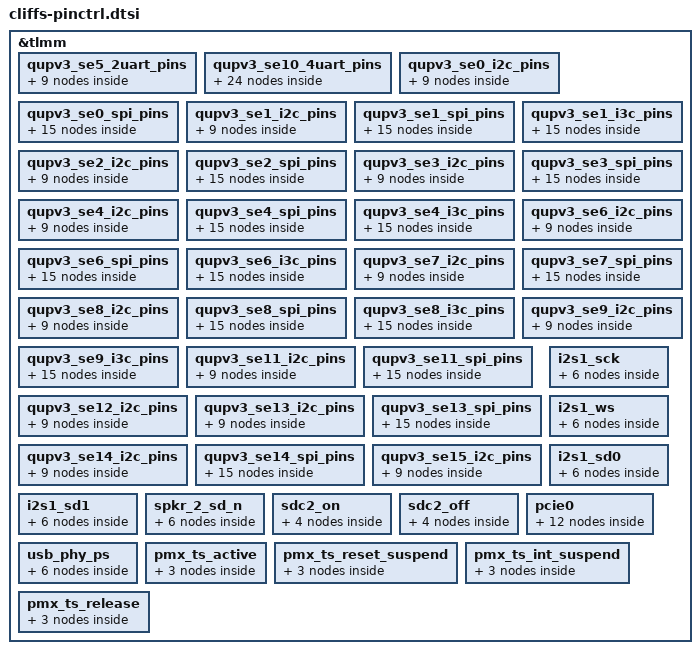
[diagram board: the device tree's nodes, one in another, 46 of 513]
&tlmm {
	qupv3_se5_2uart_pins: qupv3_se5_2uart_pins {
		qupv3_se5_2uart_tx_active: qupv3_se5_2uart_tx_active {
			mux {
				pins = "gpio22";
				function = "qup0_se5_l2";
			};

			config {
				pins = "gpio22";
				drive-strength = <2>;
				bias-disable;
			};
		};

		qupv3_se5_2uart_rx_active: qupv3_se5_2uart_rx_active {
			mux {
				pins = "gpio23";
				function = "qup0_se5_l3";
			};

			config {
				pins = "gpio23";
				drive-strength = <2>;
				bias-disable;
			};
		};

		qupv3_se5_2uart_sleep: qupv3_se5_2uart_sleep {
			mux {
				pins = "gpio22", "gpio23";
				function = "gpio";
			};

			config {
				pins = "gpio22", "gpio23";
				drive-strength = <2>;
				bias-pull-down;
			};
		};
	};

	qupv3_se10_4uart_pins: qupv3_se10_4uart_pins {
		qupv3_se10_default_cts: qupv3_se10_default_cts {
			mux {
				pins = "gpio40";
				function = "gpio";
			};

			config {
				pins = "gpio40";
				drive-strength = <2>;
				bias-disable;
			};
		};

		qupv3_se10_default_rts: qupv3_se10_default_rts {
			mux {
				pins = "gpio41";
				function = "gpio";
			};

			config {
				pins = "gpio41";
				drive-strength = <2>;
				bias-pull-down;
			};
		};

		qupv3_se10_default_tx: qupv3_se10_default_tx {
			mux {
				pins = "gpio42";
				function = "gpio";
			};

			config {
				pins = "gpio42";
				drive-strength = <2>;
				bias-pull-up;
			};
		};

		qupv3_se10_default_rx: qupv3_se10_default_rx {
			mux {
				pins = "gpio43";
				function = "gpio";
			};

			config {
				pins = "gpio43";
				drive-strength = <2>;
				bias-pull-down;
			};
		};

		qupv3_se10_cts: qupv3_se10_cts {
			mux {
				pins = "gpio40";
				function = "qup1_se2_l0";
			};

			config {
				pins = "gpio40";
				drive-strength = <2>;
				bias-disable;
			};
		};

		qupv3_se10_rts: qupv3_se10_rts {
			mux {
				pins = "gpio41";
				function = "qup1_se2_l1";
			};

			config {
				pins = "gpio41";
				drive-strength = <2>;
				bias-pull-down;
			};
		};

		qupv3_se10_tx: qupv3_se10_tx {
			mux {
				pins = "gpio42";
				function = "qup1_se2_l2";
			};

			config {
				pins = "gpio42";
				drive-strength = <2>;
				bias-pull-up;
			};
		};

		qupv3_se10_rx: qupv3_se10_rx {
			mux {
				pins = "gpio43";
				function = "qup1_se2_l3";
			};

			config {
				pins = "gpio43";
				drive-strength = <2>;
				bias-disable;
			};
		};
	};

	qupv3_se0_i2c_pins: qupv3_se0_i2c_pins {
		qupv3_se0_i2c_sda_active: qupv3_se0_i2c_sda_active {
			mux {
				pins = "gpio52";
				function = "qup0_se0_l0";
			};

			config {
				pins = "gpio52";
				drive-strength = <2>;
				bias-pull-up;
				qcom,i2c_pull;
			};
		};

		qupv3_se0_i2c_scl_active: qupv3_se0_i2c_scl_active {
			mux {
				pins = "gpio53";
				function = "qup0_se0_l1";
			};

			config {
				pins = "gpio53";
				drive-strength = <2>;
				bias-pull-up;
				qcom,i2c_pull;
			};
		};

		qupv3_se0_i2c_sleep: qupv3_se0_i2c_sleep {
			mux {
				pins = "gpio52", "gpio53";
				function = "gpio";
			};

			config {
				pins = "gpio52", "gpio53";
				drive-strength = <2>;
				//bias-disable; - Has strong PU
			};
		};
	};

	qupv3_se0_spi_pins: qupv3_se0_spi_pins {
		qupv3_se0_spi_miso_active: qupv3_se0_spi_miso_active {
			mux {
				pins = "gpio52";
				function = "qup0_se0_l0";
			};

			config {
				pins = "gpio52";
				drive-strength = <6>;
				bias-disable;
			};
		};

		qupv3_se0_spi_mosi_active: qupv3_se0_spi_mosi_active {
			mux {
				pins = "gpio53";
				function = "qup0_se0_l1";
			};

			config {
				pins = "gpio53";
				drive-strength = <6>;
				bias-disable;
			};
		};

		qupv3_se0_spi_clk_active: qupv3_se0_spi_clk_active {
			mux {
				pins = "gpio54";
				function = "qup0_se0_l2";
			};

			config {
				pins = "gpio54";
				drive-strength = <6>;
				bias-disable;
			};
		};

		qupv3_se0_spi_cs_active: qupv3_se0_spi_cs_active {
			mux {
				pins = "gpio55";
				function = "qup0_se0_l3";
			};

			config {
				pins = "gpio55";
				drive-strength = <6>;
				bias-disable;
			};
		};

		qupv3_se0_spi_sleep: qupv3_se0_spi_sleep {
			mux {
				pins = "gpio52", "gpio53",
					"gpio54", "gpio55";
				function = "gpio";
			};

			config {
				pins = "gpio52", "gpio53",
					"gpio54", "gpio55";
				drive-strength = <2>;
				bias-disable;
			};
		};
	};

	qupv3_se1_i2c_pins: qupv3_se1_i2c_pins {
		qupv3_se1_i2c_sda_active: qupv3_se1_i2c_sda_active {
			mux {
				pins = "gpio4";
				function = "qup0_se1_l0";
			};

			config {
				pins = "gpio4";
				drive-strength = <2>;
				bias-pull-up;
			};
		};

		qupv3_se1_i2c_scl_active: qupv3_se1_i2c_scl_active {
			mux {
				pins = "gpio5";
				function = "qup0_se1_l1";
			};

			config {
				pins = "gpio5";
				drive-strength = <2>;
				bias-pull-up;
			};
		};

		qupv3_se1_i2c_sleep: qupv3_se1_i2c_sleep {
			mux {
				pins = "gpio4", "gpio5";
				function = "gpio";
			};

			config {
				pins = "gpio4", "gpio5";
				drive-strength = <2>;
				bias-disable;
			};
		};
	};

	qupv3_se1_spi_pins: qupv3_se1_spi_pins {
		qupv3_se1_spi_miso_active: qupv3_se1_spi_miso_active {
			mux {
				pins = "gpio4";
				function = "qup0_se1_l0";
			};

			config {
				pins = "gpio4";
				drive-strength = <6>;
				bias-disable;
			};
		};

		qupv3_se1_spi_mosi_active: qupv3_se1_spi_mosi_active {
			mux {
				pins = "gpio5";
				function = "qup0_se1_l1";
			};

			config {
				pins = "gpio5";
				drive-strength = <6>;
				bias-disable;
			};
		};

		qupv3_se1_spi_clk_active: qupv3_se1_spi_clk_active {
			mux {
				pins = "gpio6";
				function = "qup0_se1_l2";
			};

			config {
				pins = "gpio6";
				drive-strength = <6>;
				bias-disable;
			};
		};

		qupv3_se1_spi_cs_active: qupv3_se1_spi_cs_active {
			mux {
				pins = "gpio7";
				function = "qup0_se1_l3";
			};

			config {
				pins = "gpio7";
				drive-strength = <6>;
				bias-disable;
			};
		};

		qupv3_se1_spi_sleep: qupv3_se1_spi_sleep {
			mux {
				pins = "gpio4", "gpio5",
					"gpio6", "gpio7";
				function = "gpio";
			};

			config {
				pins = "gpio4", "gpio5",
					"gpio6", "gpio7";
				drive-strength = <2>;
				bias-disable;
			};
		};
	};

	qupv3_se1_i3c_pins: qupv3_se1_i3c_pins {
		qupv3_se1_i3c_sda_active: qupv3_se1_i3c_sda_active {
			mux {
				pins = "gpio4";
				function = "ibi_i3c";
			};

			config {
				pins = "gpio4";
				drive-strength = <16>;
				bias-pull-up;
			};
		};

		qupv3_se1_i3c_scl_active: qupv3_se1_i3c_scl_active {
			mux {
				pins = "gpio5";
				function = "ibi_i3c";
			};

			config {
				pins = "gpio5";
				drive-strength = <16>;
				bias-pull-up;
			};
		};

		qupv3_se1_i3c_sda_sleep: qupv3_se1_i3c_sda_sleep {
			mux {
				pins = "gpio4";
				function = "ibi_i3c";
			};

			config {
				pins = "gpio4";
				drive-strength = <16>;
				bias-pull-up;
			};
		};

		qupv3_se1_i3c_scl_sleep: qupv3_se1_i3c_scl_sleep {
			mux {
				pins = "gpio5";
				function = "ibi_i3c";
			};

			config {
				pins = "gpio5";
				drive-strength = <16>;
				bias-pull-up;
			};
		};

		qupv3_se1_i3c_disable: qupv3_se1_i3c_disable {
			mux {
				pins = "gpio4", "gpio5";
				function = "gpio";
			};

			config {
				pins = "gpio4", "gpio5";
				drive-strength = <2>;
				bias-disable;
			};
		};
	};

	qupv3_se2_i2c_pins: qupv3_se2_i2c_pins {
		qupv3_se2_i2c_sda_active: qupv3_se2_i2c_sda_active {
			mux {
				pins = "gpio8";
				function = "qup0_se2_l0";
			};

			config {
				pins = "gpio8";
				drive-strength = <2>;
				bias-pull-up;
				qcom,i2c_pull;
			};
		};

		qupv3_se2_i2c_scl_active: qupv3_se2_i2c_scl_active {
			mux {
				pins = "gpio9";
				function = "qup0_se2_l1";
			};

			config {
				pins = "gpio9";
				drive-strength = <2>;
				bias-pull-up;
				qcom,i2c_pull;
			};
		};

		qupv3_se2_i2c_sleep: qupv3_se2_i2c_sleep {
			mux {
				pins = "gpio8", "gpio9";
				function = "gpio";
			};

			config {
				pins = "gpio8", "gpio9";
				drive-strength = <2>;
				//bias-disable; - Has strong PU
			};
		};
	};

	qupv3_se2_spi_pins: qupv3_se2_spi_pins {
		qupv3_se2_spi_miso_active: qupv3_se2_spi_miso_active {
			mux {
				pins = "gpio8";
				function = "qup0_se2_l0";
			};

			config {
				pins = "gpio8";
				drive-strength = <6>;
				bias-disable;
			};
		};

		qupv3_se2_spi_mosi_active: qupv3_se2_spi_mosi_active {
			mux {
				pins = "gpio9";
				function = "qup0_se2_l1";
			};

			config {
				pins = "gpio9";
				drive-strength = <6>;
				bias-disable;
			};
		};

		qupv3_se2_spi_clk_active: qupv3_se2_spi_clk_active {
			mux {
				pins = "gpio10";
				function = "qup0_se2_l2";
			};

			config {
				pins = "gpio10";
				drive-strength = <6>;
				bias-disable;
			};
		};

		qupv3_se2_spi_cs_active: qupv3_se2_spi_cs_active {
			mux {
				pins = "gpio11";
				function = "qup0_se2_l3";
			};

			config {
				pins = "gpio11";
				drive-strength = <6>;
				bias-disable;
			};
		};

		qupv3_se2_spi_sleep: qupv3_se2_spi_sleep {
			mux {
				pins = "gpio8", "gpio9",
					"gpio10", "gpio11";
				function = "gpio";
			};

			config {
				pins = "gpio8", "gpio9",
					"gpio10", "gpio11";
				drive-strength = <2>;
				bias-disable;
			};
		};
	};

	qupv3_se3_i2c_pins: qupv3_se3_i2c_pins {
		qupv3_se3_i2c_sda_active: qupv3_se3_i2c_sda_active {
			mux {
				pins = "gpio12";
				function = "qup0_se3_l0";
			};

			config {
				pins = "gpio12";
				drive-strength = <2>;
				bias-pull-up;
			};
		};

		qupv3_se3_i2c_scl_active: qupv3_se3_i2c_scl_active {
			mux {
				pins = "gpio13";
				function = "qup0_se3_l1";
			};

			config {
				pins = "gpio13";
				drive-strength = <2>;
				bias-pull-up;
			};
		};

		qupv3_se3_i2c_sleep: qupv3_se3_i2c_sleep {
			mux {
				pins = "gpio12", "gpio13";
				function = "gpio";
			};

			config {
				pins = "gpio12", "gpio13";
				drive-strength = <2>;
				bias-disable;
			};
		};
	};

	qupv3_se3_spi_pins: qupv3_se3_spi_pins {
		qupv3_se3_spi_miso_active: qupv3_se3_spi_miso_active {
			mux {
				pins = "gpio12";
				function = "qup0_se3_l0";
			};

			config {
				pins = "gpio12";
				drive-strength = <6>;
				bias-disable;
			};
		};

		qupv3_se3_spi_mosi_active: qupv3_se3_spi_mosi_active {
			mux {
				pins = "gpio13";
				function = "qup0_se3_l1";
			};

			config {
				pins = "gpio13";
				drive-strength = <6>;
				bias-disable;
			};
		};

		qupv3_se3_spi_clk_active: qupv3_se3_spi_clk_active {
			mux {
				pins = "gpio14";
				function = "qup1_se3_l2";
			};

			config {
				pins = "gpio14";
				drive-strength = <6>;
				bias-disable;
			};
		};

		qupv3_se3_spi_cs_active: qupv3_se3_spi_cs_active {
			mux {
				pins = "gpio15";
				function = "qup0_se3_l3";
			};

			config {
				pins = "gpio15";
				drive-strength = <6>;
				bias-disable;
			};
		};

		qupv3_se3_spi_sleep: qupv3_se3_spi_sleep {
			mux {
				pins = "gpio12", "gpio13",
					"gpio14", "gpio15";
				function = "gpio";
			};

			config {
				pins = "gpio12", "gpio13",
					"gpio14", "gpio15";
				drive-strength = <2>;
				bias-disable;
			};
		};
	};

	qupv3_se4_i2c_pins: qupv3_se4_i2c_pins {
		qupv3_se4_i2c_sda_active: qupv3_se4_i2c_sda_active {
			mux {
				pins = "gpio16";
				function = "qup0_se4_l0";
			};

			config {
				pins = "gpio16";
				drive-strength = <2>;
				bias-pull-up;
			};
		};

		qupv3_se4_i2c_scl_active: qupv3_se4_i2c_scl_active {
			mux {
				pins = "gpio17";
				function = "qup0_se4_l1";
			};

			config {
				pins = "gpio17";
				drive-strength = <2>;
				bias-pull-up;
			};
		};

		qupv3_se4_i2c_sleep: qupv3_se4_i2c_sleep {
			mux {
				pins = "gpio16", "gpio17";
				function = "gpio";
			};

			config {
				pins = "gpio16", "gpio17";
				drive-strength = <2>;
				bias-disable;
			};
		};
	};

	qupv3_se4_spi_pins: qupv3_se4_spi_pins {
		qupv3_se4_spi_miso_active: qupv3_se4_spi_miso_active {
			mux {
				pins = "gpio16";
				function = "qup0_se4_l0";
			};

			config {
				pins = "gpio16";
				drive-strength = <6>;
				bias-disable;
			};
		};

		qupv3_se4_spi_mosi_active: qupv3_se4_spi_mosi_active {
			mux {
				pins = "gpio17";
				function = "qup0_se4_l1";
			};

			config {
				pins = "gpio17";
				drive-strength = <6>;
				bias-disable;
			};
		};

		qupv3_se4_spi_clk_active: qupv3_se4_spi_clk_active {
			mux {
				pins = "gpio18";
				function = "qup0_se4_l2";
			};

			config {
				pins = "gpio18";
				drive-strength = <6>;
				bias-disable;
			};
		};

		qupv3_se4_spi_cs_active: qupv3_se4_spi_cs_active {
			mux {
				pins = "gpio19";
				function = "qup0_se4_l3";
			};

			config {
				pins = "gpio19";
				drive-strength = <6>;
				bias-disable;
			};
		};

		qupv3_se4_spi_sleep: qupv3_se4_spi_sleep {
			mux {
				pins = "gpio16", "gpio17",
					"gpio18", "gpio19";
				function = "gpio";
			};

			config {
				pins = "gpio16", "gpio17",
					"gpio18", "gpio19";
				drive-strength = <2>;
				bias-disable;
			};
		};
	};

	qupv3_se4_i3c_pins: qupv3_se4_i3c_pins {
		qupv3_se4_i3c_sda_active: qupv3_se4_i3c_sda_active {
			mux {
				pins = "gpio16";
				function = "ibi_i3c";
			};

			config {
				pins = "gpio16";
				drive-strength = <16>;
				bias-pull-up;
			};
		};

		qupv3_se4_i3c_scl_active: qupv3_se4_i3c_scl_active {
			mux {
				pins = "gpio17";
				function = "ibi_i3c";
			};

			config {
				pins = "gpio17";
				drive-strength = <16>;
				bias-pull-up;
			};
		};

		qupv3_se4_i3c_sda_sleep: qupv3_se4_i3c_sda_sleep {
			mux {
				pins = "gpio16";
				function = "ibi_i3c";
			};

			config {
				pins = "gpio16";
				drive-strength = <16>;
				bias-pull-up;
			};
		};

		qupv3_se4_i3c_scl_sleep: qupv3_se4_i3c_scl_sleep {
			mux {
				pins = "gpio17";
				function = "ibi_i3c";
			};

			config {
				pins = "gpio17";
				drive-strength = <16>;
				bias-pull-up;
			};
		};

		qupv3_se4_i3c_disable: qupv3_se4_i3c_disable {
			mux {
				pins = "gpio16", "gpio17";
				function = "gpio";
			};

			config {
				pins = "gpio16", "gpio17";
				drive-strength = <2>;
				bias-disable;
			};
		};
	};

	qupv3_se6_i2c_pins: qupv3_se6_i2c_pins {
		qupv3_se6_i2c_sda_active: qupv3_se6_i2c_sda_active {
			mux {
				pins = "gpio24";
				function = "qup0_se6_l0";
			};

			config {
				pins = "gpio24";
				drive-strength = <2>;
				bias-pull-up;
			};
		};

		qupv3_se6_i2c_scl_active: qupv3_se6_i2c_scl_active {
			mux {
				pins = "gpio25";
				function = "qup0_se6_l1";
			};

			config {
				pins = "gpio25";
				drive-strength = <2>;
				bias-pull-up;
			};
		};

		qupv3_se6_i2c_sleep: qupv3_se6_i2c_sleep {
			mux {
				pins = "gpio24", "gpio25";
				function = "gpio";
			};

			config {
				pins = "gpio24", "gpio25";
				drive-strength = <2>;
				bias-disable;
			};
		};
	};

	qupv3_se6_spi_pins: qupv3_se6_spi_pins {
		qupv3_se6_spi_miso_active: qupv3_se6_spi_miso_active {
			mux {
				pins = "gpio24";
				function = "qup0_se6_l0";
			};

			config {
				pins = "gpio24";
				drive-strength = <6>;
				bias-disable;
			};
		};

		qupv3_se6_spi_mosi_active: qupv3_se6_spi_mosi_active {
			mux {
				pins = "gpio25";
				function = "qup0_se6_l1";
			};

			config {
				pins = "gpio25";
				drive-strength = <6>;
				bias-disable;
			};
		};

		qupv3_se6_spi_clk_active: qupv3_se6_spi_clk_active {
			mux {
				pins = "gpio26";
				function = "qup0_se6_l2";
			};

			config {
				pins = "gpio26";
				drive-strength = <6>;
				bias-disable;
			};
		};

		qupv3_se6_spi_cs_active: qupv3_se6_spi_cs_active {
			mux {
				pins = "gpio27";
				function = "qup0_se6_l3";
			};

			config {
				pins = "gpio27";
				drive-strength = <6>;
				bias-disable;
			};
		};

		qupv3_se6_spi_sleep: qupv3_se6_spi_sleep {
			mux {
				pins = "gpio24", "gpio25",
					"gpio26", "gpio27";
				function = "gpio";
			};

			config {
				pins = "gpio24", "gpio25",
					"gpio26", "gpio27";
				drive-strength = <2>;
				bias-disable;
			};
		};
	};

	qupv3_se6_i3c_pins: qupv3_se6_i3c_pins {
		qupv3_se6_i3c_sda_active: qupv3_se6_i3c_sda_active {
			mux {
				pins = "gpio24";
				function = "ibi_i3c";
			};

			config {
				pins = "gpio24";
				drive-strength = <16>;
				bias-pull-up;
			};
		};

		qupv3_se6_i3c_scl_active: qupv3_se6_i3c_scl_active {
			mux {
				pins = "gpio25";
				function = "ibi_i3c";
			};

			config {
				pins = "gpio25";
				drive-strength = <16>;
				bias-pull-up;
			};
		};

		qupv3_se6_i3c_sda_sleep: qupv3_se6_i3c_sda_sleep {
			mux {
				pins = "gpio24";
				function = "ibi_i3c";
			};

			config {
				pins = "gpio24";
				drive-strength = <16>;
				bias-pull-up;
			};
		};

		qupv3_se6_i3c_scl_sleep: qupv3_se6_i3c_scl_sleep {
			mux {
				pins = "gpio25";
				function = "ibi_i3c";
			};

			config {
				pins = "gpio25";
				drive-strength = <16>;
				bias-pull-up;
			};
		};

		qupv3_se6_i3c_disable: qupv3_se6_i3c_disable {
			mux {
				pins = "gpio24", "gpio25";
				function = "gpio";
			};

			config {
				pins = "gpio24", "gpio25";
				drive-strength = <2>;
				bias-disable;
			};
		};
	};

	qupv3_se7_i2c_pins: qupv3_se7_i2c_pins {
		qupv3_se7_i2c_sda_active: qupv3_se7_i2c_sda_active {
			mux {
				pins = "gpio28";
				function = "qup0_se7_l0";
			};

			config {
				pins = "gpio28";
				drive-strength = <2>;
				bias-pull-up;
				qcom,i2c_pull;
			};
		};

		qupv3_se7_i2c_scl_active: qupv3_se7_i2c_scl_active {
			mux {
				pins = "gpio29";
				function = "qup0_se7_l1";
			};

			config {
				pins = "gpio29";
				drive-strength = <2>;
				bias-pull-up;
				qcom,i2c_pull;
			};
		};

		qupv3_se7_i2c_sleep: qupv3_se7_i2c_sleep {
			mux {
				pins = "gpio28", "gpio29";
				function = "gpio";
			};

			config {
				pins = "gpio28", "gpio29";
				drive-strength = <2>;
				//bias-disable; - Has strong PU
			};
		};
	};

	qupv3_se7_spi_pins: qupv3_se7_spi_pins {
		qupv3_se7_spi_miso_active: qupv3_se7_spi_miso_active {
			mux {
				pins = "gpio28";
				function = "qup0_se7_l0";
			};

			config {
				pins = "gpio28";
				drive-strength = <6>;
				bias-disable;
			};
		};

		qupv3_se7_spi_mosi_active: qupv3_se7_spi_mosi_active {
			mux {
				pins = "gpio29";
				function = "qup0_se7_l1";
			};

			config {
				pins = "gpio29";
				drive-strength = <6>;
				bias-disable;
			};
		};

		qupv3_se7_spi_clk_active: qupv3_se7_spi_clk_active {
			mux {
				pins = "gpio30";
				function = "qup0_se7_l2";
			};

			config {
				pins = "gpio30";
				drive-strength = <6>;
				bias-disable;
			};
		};

		qupv3_se7_spi_cs_active: qupv3_se7_spi_cs_active {
			mux {
				pins = "gpio31";
				function = "qup0_se7_l3";
			};

			config {
				pins = "gpio31";
				drive-strength = <6>;
				bias-disable;
			};
		};

		qupv3_se7_spi_sleep: qupv3_se7_spi_sleep {
			mux {
				pins = "gpio28", "gpio29",
					"gpio30", "gpio31";
				function = "gpio";
			};

			config {
				pins = "gpio28", "gpio29",
					"gpio30", "gpio31";
				drive-strength = <2>;
				bias-disable;
			};
		};
	};

	qupv3_se8_i2c_pins: qupv3_se8_i2c_pins {
		qupv3_se8_i2c_sda_active: qupv3_se8_i2c_sda_active {
			mux {
				pins = "gpio0";
				function = "qup1_se0_l0";
			};

			config {
				pins = "gpio0";
				drive-strength = <2>;
				bias-pull-up;
				qcom,apps;
			};
		};

		qupv3_se8_i2c_scl_active: qupv3_se8_i2c_scl_active {
			mux {
				pins = "gpio1";
				function = "qup1_se0_l1";
			};

			config {
				pins = "gpio1";
				drive-strength = <2>;
				bias-pull-up;
				qcom,apps;
			};
		};

		qupv3_se8_i2c_sleep: qupv3_se8_i2c_sleep {
			mux {
				pins = "gpio0", "gpio1";
				function = "gpio";
			};

			config {
				pins = "gpio0", "gpio1";
				drive-strength = <2>;
				bias-pull-down;
				qcom,remote;
			};
		};
	};

	qupv3_se8_spi_pins: qupv3_se8_spi_pins {
		qupv3_se8_spi_miso_active: qupv3_se8_spi_miso_active {
			mux {
				pins = "gpio0";
				function = "qup1_se0_l0";
			};

			config {
				pins = "gpio0";
				drive-strength = <6>;
				bias-disable;
			};
		};

		qupv3_se8_spi_mosi_active: qupv3_se8_spi_mosi_active {
			mux {
				pins = "gpio1";
				function = "qup1_se0_l1";
			};

			config {
				pins = "gpio1";
				drive-strength = <6>;
				bias-disable;
			};
		};

		qupv3_se8_spi_clk_active: qupv3_se8_spi_clk_active {
			mux {
				pins = "gpio2";
				function = "qup1_se0_l2";
			};

			config {
				pins = "gpio2";
				drive-strength = <6>;
				bias-disable;
			};
		};

		qupv3_se8_spi_cs_active: qupv3_se8_spi_cs_active {
			mux {
				pins = "gpio3";
				function = "qup1_se0_l3";
			};

			config {
				pins = "gpio3";
				drive-strength = <6>;
				bias-disable;
			};
		};

		qupv3_se8_spi_sleep: qupv3_se8_spi_sleep {
			mux {
				pins = "gpio0", "gpio1",
					"gpio2", "gpio3";
				function = "gpio";
			};

			config {
				pins = "gpio0", "gpio1",
					"gpio2", "gpio3";
				drive-strength = <2>;
				bias-disable;
			};
		};
	};

	qupv3_se8_i3c_pins: qupv3_se8_i3c_pins {
		qupv3_se8_i3c_sda_active: qupv3_se8_i3c_sda_active {
			mux {
				pins = "gpio0";
				function = "ibi_i3c";
			};

			config {
				pins = "gpio0";
				drive-strength = <16>;
				bias-pull-up;
			};
		};

		qupv3_se8_i3c_scl_active: qupv3_se8_i3c_scl_active {
			mux {
				pins = "gpio1";
				function = "ibi_i3c";
			};

			config {
				pins = "gpio1";
				drive-strength = <16>;
				bias-pull-up;
			};
		};

		qupv3_se8_i3c_sda_sleep: qupv3_se8_i3c_sda_sleep {
			mux {
				pins = "gpio0";
				function = "ibi_i3c";
			};

			config {
				pins = "gpio0";
				drive-strength = <16>;
				bias-pull-up;
			};
		};

		qupv3_se8_i3c_scl_sleep: qupv3_se8_i3c_scl_sleep {
			mux {
				pins = "gpio1";
				function = "ibi_i3c";
			};

			config {
				pins = "gpio1";
				drive-strength = <16>;
				bias-pull-up;
			};
		};

		qupv3_se8_i3c_disable: qupv3_se8_i3c_disable {
			mux {
				pins = "gpio0", "gpio1";
				function = "gpio";
			};

			config {
				pins = "gpio0", "gpio1";
				drive-strength = <2>;
				bias-disable;
			};
		};
	};

	qupv3_se9_i2c_pins: qupv3_se9_i2c_pins {
		qupv3_se9_i2c_sda_active: qupv3_se9_i2c_sda_active {
			mux {
				pins = "gpio36";
				function = "qup1_se1_l0";
			};

			config {
				pins = "gpio36";
				drive-strength = <2>;
				bias-pull-up;
			};
		};

		qupv3_se9_i2c_scl_active: qupv3_se9_i2c_scl_active {
			mux {
				pins = "gpio37";
				function = "qup1_se1_l1";
			};

			config {
				pins = "gpio37";
				drive-strength = <2>;
				bias-pull-up;
			};
		};

		qupv3_se9_i2c_sleep: qupv3_se9_i2c_sleep {
			mux {
				pins = "gpio36", "gpio37";
				function = "gpio";
			};

			config {
				pins = "gpio36", "gpio37";
				drive-strength = <2>;
				bias-disable;
			};
		};
	};

	qupv3_se9_i3c_pins: qupv3_se9_i3c_pins {
		qupv3_se9_i3c_sda_active: qupv3_se9_i3c_sda_active {
			mux {
				pins = "gpio36";
				function = "ibi_i3c";
			};

			config {
				pins = "gpio36";
				drive-strength = <16>;
				bias-pull-up;
			};
		};

		qupv3_se9_i3c_scl_active: qupv3_se9_i3c_scl_active {
			mux {
				pins = "gpio37";
				function = "ibi_i3c";
			};

			config {
				pins = "gpio37";
				drive-strength = <16>;
				bias-pull-up;
			};
		};

		qupv3_se9_i3c_sda_sleep: qupv3_se9_i3c_sda_sleep {
			mux {
				pins = "gpio36";
				function = "ibi_i3c";
			};

			config {
				pins = "gpio36";
				drive-strength = <16>;
				bias-pull-up;
			};
		};

		qupv3_se9_i3c_scl_sleep: qupv3_se9_i3c_scl_sleep {
			mux {
				pins = "gpio37";
				function = "ibi_i3c";
			};

			config {
				pins = "gpio37";
				drive-strength = <16>;
				bias-pull-up;
			};
		};

		qupv3_se9_i3c_disable: qupv3_se9_i3c_disable {
			mux {
				pins = "gpio36", "gpio37";
				function = "gpio";
			};

			config {
				pins = "gpio36", "gpio37";
				drive-strength = <2>;
				bias-disable;
			};
		};
	};

	qupv3_se11_i2c_pins: qupv3_se11_i2c_pins {
		qupv3_se11_i2c_sda_active: qupv3_se11_i2c_sda_active {
			mux {
				pins = "gpio44";
				function = "qup1_se3_l0";
			};

			config {
				pins = "gpio44";
				drive-strength = <2>;
				bias-pull-up;
				qcom,i2c_pull;
			};
		};

		qupv3_se11_i2c_scl_active: qupv3_se11_i2c_scl_active {
			mux {
				pins = "gpio45";
				function = "qup1_se3_l1";
			};

			config {
				pins = "gpio45";
				drive-strength = <2>;
				bias-pull-up;
				qcom,i2c_pull;
			};
		};

		qupv3_se11_i2c_sleep: qupv3_se11_i2c_sleep {
			mux {
				pins = "gpio44", "gpio45";
				function = "gpio";
			};

			config {
				pins = "gpio44", "gpio45";
				drive-strength = <2>;
				//bias-disable; - Has strong PU
			};
		};
	};

	qupv3_se11_spi_pins: qupv3_se11_spi_pins {
		qupv3_se11_spi_miso_active: qupv3_se11_spi_miso_active {
			mux {
				pins = "gpio44";
				function = "qup1_se3_l0";
			};

			config {
				pins = "gpio44";
				drive-strength = <6>;
				bias-disable;
			};
		};

		qupv3_se11_spi_mosi_active: qupv3_se11_spi_mosi_active {
			mux {
				pins = "gpio45";
				function = "qup1_se3_l1";
			};

			config {
				pins = "gpio45";
				drive-strength = <6>;
				bias-disable;
			};
		};

		qupv3_se11_spi_clk_active: qupv3_se11_spi_clk_active {
			mux {
				pins = "gpio46";
				function = "qup1_se3_l2";
			};

			config {
				pins = "gpio46";
				drive-strength = <6>;
				bias-disable;
			};
		};

		qupv3_se11_spi_cs_active: qupv3_se11_spi_cs_active {
			mux {
				pins = "gpio47";
				function = "qup1_se3_l3";
			};

			config {
				pins = "gpio47";
				drive-strength = <6>;
				bias-disable;
			};
		};

		qupv3_se11_spi_sleep: qupv3_se11_spi_sleep {
			mux {
				pins = "gpio44", "gpio45",
					"gpio46", "gpio47";
				function = "gpio";
			};

			config {
				pins = "gpio44", "gpio45",
					"gpio46", "gpio47";
				drive-strength = <2>;
				bias-disable;
			};
		};
	};

	qupv3_se12_i2c_pins: qupv3_se12_i2c_pins {
		qupv3_se12_i2c_sda_active: qupv3_se12_i2c_sda_active {
			mux {
				pins = "gpio176";
				function = "qup1_se4_l0";
			};

			config {
				pins = "gpio176";
				drive-strength = <2>;
				bias-pull-up;
			};
		};

		qupv3_se12_i2c_scl_active: qupv3_se12_i2c_scl_active {
			mux {
				pins = "gpio177";
				function = "qup1_se4_l1";
			};

			config {
				pins = "gpio177";
				drive-strength = <2>;
				bias-pull-up;
			};
		};

		qupv3_se12_i2c_sleep: qupv3_se12_i2c_sleep {
			mux {
				pins = "gpio176", "gpio177";
				function = "gpio";
			};

			config {
				pins = "gpio176", "gpio177";
				drive-strength = <2>;
				bias-disable;
			};
		};
	};

	qupv3_se13_i2c_pins: qupv3_se13_i2c_pins {
		qupv3_se13_i2c_sda_active: qupv3_se13_i2c_sda_active {
			mux {
				pins = "gpio32";
				function = "qup1_se5_l0";
			};

			config {
				pins = "gpio32";
				drive-strength = <2>;
				bias-pull-up;
			};
		};

		qupv3_se13_i2c_scl_active: qupv3_se13_i2c_scl_active {
			mux {
				pins = "gpio33";
				function = "qup1_se5_l1";
			};

			config {
				pins = "gpio33";
				drive-strength = <2>;
				bias-pull-up;
			};
		};

		qupv3_se13_i2c_sleep: qupv3_se13_i2c_sleep {
			mux {
				pins = "gpio32", "gpio33";
				function = "gpio";
			};

			config {
				pins = "gpio32", "gpio33";
				drive-strength = <2>;
				bias-disable;
			};
		};
	};

	qupv3_se13_spi_pins: qupv3_se13_spi_pins {
		qupv3_se13_spi_miso_active: qupv3_se13_spi_miso_active {
			mux {
				pins = "gpio32";
				function = "qup1_se5_l0";
			};

			config {
				pins = "gpio32";
				drive-strength = <6>;
				bias-disable;
			};
		};

		qupv3_se13_spi_mosi_active: qupv3_se13_spi_mosi_active {
			mux {
				pins = "gpio33";
				function = "qup1_se5_l1";
			};

			config {
				pins = "gpio33";
				drive-strength = <6>;
				bias-disable;
			};
		};

		qupv3_se13_spi_clk_active: qupv3_se13_spi_clk_active {
			mux {
				pins = "gpio34";
				function = "qup1_se5_l2";
			};

			config {
				pins = "gpio34";
				drive-strength = <6>;
				bias-disable;
			};
		};

		qupv3_se13_spi_cs_active: qupv3_se13_spi_cs_active {
			mux {
				pins = "gpio35";
				function = "qup1_se5_l3";
			};

			config {
				pins = "gpio35";
				drive-strength = <6>;
				bias-disable;
			};
		};

		qupv3_se13_spi_sleep: qupv3_se13_spi_sleep {
			mux {
				pins = "gpio32", "gpio33",
					"gpio34", "gpio35";
				function = "gpio";
			};

			config {
				pins = "gpio32", "gpio33",
					"gpio34", "gpio35";
				drive-strength = <2>;
				bias-disable;
			};
		};
	};

	qupv3_se14_i2c_pins: qupv3_se14_i2c_pins {
		qupv3_se14_i2c_sda_active: qupv3_se14_i2c_sda_active {
			mux {
				pins = "gpio56";
				function = "qup1_se6_l0";
			};

			config {
				pins = "gpio56";
				drive-strength = <2>;
				bias-pull-up;
				qcom,i2c_pull;
			};
		};

		qupv3_se14_i2c_scl_active: qupv3_se14_i2c_scl_active {
			mux {
				pins = "gpio57";
				function = "qup1_se6_l1";
			};

			config {
				pins = "gpio57";
				drive-strength = <2>;
				bias-pull-up;
				qcom,i2c_pull;
			};
		};

		qupv3_se14_i2c_sleep: qupv3_se14_i2c_sleep {
			mux {
				pins = "gpio56", "gpio57";
				function = "gpio";
			};

			config {
				pins = "gpio56", "gpio57";
				drive-strength = <2>;
				//bias-disable; - Has strong PU
			};
		};
	};

	qupv3_se14_spi_pins: qupv3_se14_spi_pins {
		qupv3_se14_spi_miso_active: qupv3_se14_spi_miso_active {
			mux {
				pins = "gpio56";
				function = "qup1_se6_l0";
			};

			config {
				pins = "gpio56";
				drive-strength = <6>;
				bias-disable;
			};
		};

		qupv3_se14_spi_mosi_active: qupv3_se14_spi_mosi_active {
			mux {
				pins = "gpio57";
				function = "qup1_se6_l1";
			};

			config {
				pins = "gpio57";
				drive-strength = <6>;
				bias-disable;
			};
		};

		qupv3_se14_spi_clk_active: qupv3_se14_spi_clk_active {
			mux {
				pins = "gpio58";
				function = "qup1_se6_l2";
			};

			config {
				pins = "gpio58";
				drive-strength = <6>;
				bias-disable;
			};
		};

		qupv3_se14_spi_cs_active: qupv3_se14_spi_cs_active {
			mux {
				pins = "gpio59";
				function = "qup1_se6_l3";
			};

			config {
				pins = "gpio59";
				drive-strength = <6>;
				bias-disable;
			};
		};

		qupv3_se14_spi_sleep: qupv3_se14_spi_sleep {
			mux {
				pins = "gpio56", "gpio57",
					"gpio58", "gpio59";
				function = "gpio";
			};

			config {
				pins = "gpio56", "gpio57",
					"gpio58", "gpio59";
				drive-strength = <2>;
				bias-disable;
			};
		};
	};

	qupv3_se15_i2c_pins: qupv3_se15_i2c_pins {
		qupv3_se15_i2c_sda_active: qupv3_se15_i2c_sda_active {
			mux {
				pins = "gpio60";
				function = "qup1_se7_l0";
			};

			config {
				pins = "gpio60";
				drive-strength = <2>;
				bias-pull-up;
			};
		};

		qupv3_se15_i2c_scl_active: qupv3_se15_i2c_scl_active {
			mux {
				pins = "gpio61";
				function = "qup1_se7_l1";
			};

			config {
				pins = "gpio61";
				drive-strength = <2>;
				bias-pull-up;
			};
		};

		qupv3_se15_i2c_sleep: qupv3_se15_i2c_sleep {
			mux {
				pins = "gpio60", "gpio61";
				function = "gpio";
			};

			config {
				pins = "gpio60", "gpio61";
				drive-strength = <2>;
				bias-disable;
			};
		};
	};

	i2s1_sck {
		i2s1_sck_sleep: i2s1_sck_sleep {
			mux {
				pins = "gpio123";
				function = "gpio";
			};

			config {
				pins = "gpio123";
				drive-strength = <2>;   /* 2 mA */
				bias-pull-down;         /* PULL DOWN */
				input-enable;
			};
		};

		i2s1_sck_active: i2s1_sck_active {
			mux {
				pins = "gpio123";
				function = "i2s1_sck";
			};

			config {
				pins = "gpio123";
				drive-strength = <8>;   /* 8 mA */
				bias-disable;           /* NO PULL */
			};
		};
	};

	i2s1_ws {
		i2s1_ws_sleep: i2s1_ws_sleep {
			mux {
				pins = "gpio125";
				function = "gpio";
			};

			config {
				pins = "gpio125";
				drive-strength = <2>;   /* 2 mA */
				bias-pull-down;         /* PULL DOWN */
				input-enable;
			};
		};

		i2s1_ws_active: i2s1_ws_active {
			mux {
				pins = "gpio125";
				function = "i2s1_ws";
			};

			config {
				pins = "gpio125";
				drive-strength = <8>;   /* 8 mA */
				bias-disable;           /* NO PULL */
			};
		};
	};

	i2s1_sd0 {
		i2s1_sd0_sleep: i2s1_sd0_sleep {
			mux {
				pins = "gpio124";
				function = "gpio";
			};

			config {
				pins = "gpio124";
				drive-strength = <2>;   /* 2 mA */
				bias-pull-down;         /* PULL DOWN */
				input-enable;
			};
		};

		i2s1_sd0_active: i2s1_sd0_active {
			mux {
				pins = "gpio124";
				function = "i2s1_data0";
			};

			config {
				pins = "gpio124";
				drive-strength = <8>;   /* 8 mA */
				bias-disable;           /* NO PULL */
			};
		};
	};

	i2s1_sd1 {
		i2s1_sd1_sleep: i2s1_sd1_sleep {
			mux {
				pins = "gpio126";
				function = "gpio";
			};

			config {
				pins = "gpio126";
				drive-strength = <2>;   /* 2 mA */
				bias-pull-down;         /* PULL DOWN */
				input-enable;
			};
		};

		i2s1_sd1_active: i2s1_sd1_active {
			mux {
				pins = "gpio126";
				function = "i2s1_data1";
			};

			config {
				pins = "gpio126";
				drive-strength = <8>;   /* 8 mA */
				bias-disable;           /* NO PULL */
			};
		};
	};

	/* WSA speaker reset pins */
	spkr_2_sd_n {
		spkr_2_sd_n_sleep: spkr_2_sd_n_sleep {
			mux {
				pins = "gpio76";
				function = "gpio";
			};

			config {
				pins = "gpio76";
				drive-strength = <2>;   /* 2 mA */
				bias-pull-down;
				input-enable;
			};
		};

		spkr_2_sd_n_active: spkr_2_sd_n_active {
			mux {
				pins = "gpio76";
				function = "gpio";
			};

			config {
				pins = "gpio76";
				drive-strength = <16>;   /* 16 mA */
				bias-disable;
				output-high;
			};
		};
	};

	sdc2_on: sdc2_on {
		clk {
			pins = "gpio62";
			function = "sdc2_clk";
			bias-disable;
			drive-strength = <16>;
		};

		cmd {
			pins = "gpio51";
			function = "sdc2_cmd";
			bias-pull-up;
			drive-strength = <10>;
		};

		data {
			pins = "gpio38", "gpio39", "gpio48", "gpio49";
			function = "sdc2_data";
			bias-pull-up;
			drive-strength = <10>;
		};

		sd-cd {
			pins = "gpio31";
			bias-pull-up;
			drive-strength = <2>;
		};
	};

	sdc2_off: sdc2_off {
		clk {
			pins = "gpio62";
			function = "gpio";
			bias-disable;
			drive-strength = <2>;
		};

		cmd {
			pins = "gpio51";
			function = "gpio";
			bias-pull-up;
			drive-strength = <2>;
		};

		data {
			pins = "gpio38", "gpio39", "gpio48", "gpio49";
			function = "gpio";
			bias-pull-up;
			drive-strength = <2>;
		};

		sd-cd {
			pins = "gpio31";
			bias-pull-up;
			drive-strength = <2>;
		};
	};

	pcie0 {
		pcie0_perst_default: pcie0_perst_default {
			mux {
				pins = "gpio33";
				function = "gpio";
			};

			config {
				pins = "gpio33";
				drive-strength = <2>;
				bias-pull-down;
			};
		};

		pcie0_clkreq_default: pcie0_clkreq_default {
			mux {
				pins = "gpio118";
				function = "pcie0_clk_req_n";
			};

			config {
				pins = "gpio118";
				drive-strength = <2>;
				bias-pull-up;
			};
		};

		pcie0_wake_default: pcie0_wake_default {
			mux {
				pins = "gpio81";
				function = "gpio";
			};

			config {
				pins = "gpio81";
				drive-strength = <2>;
				bias-pull-up;
			};
		};

		pcie0_clkreq_sleep: pcie0_clkreq_sleep {
			mux {
				pins = "gpio118";
				function = "gpio";
			};

			config {
				pins = "gpio118";
				drive-strength = <2>;
				bias-pull-up;
				input-enable;
			};
		};
	};

	usb_phy_ps: usb_phy_ps {
		usb3phy_portselect_default: usb3phy_portselect_default {
			mux {
				pins = "gpio122";
				function = "usb0_phy_ps";
			};

			config {
				pins = "gpio122";
				bias-pull-down;
				drive-strength = <2>;
			};
		};

		usb3phy_portselect_gpio: usb3phy_portselect_gpio {
			mux {
				pins = "gpio122";
				function = "gpio";
			};

			config {
				pins = "gpio122";
				drive-strength = <2>;
				bias-pull-down;
				input-enable;
			};
		};
	};

	/* touchscreen pins */
	pmx_ts_active {
		ts_active: ts_active {
			mux {
				pins = "gpio128", "gpio129";
				function = "gpio";
			};

			config {
				pins = "gpio128", "gpio129";
				drive-strength = <8>;
				bias-pull-up;
			};
		};
	};

	pmx_ts_reset_suspend {
		ts_reset_suspend: ts_reset_suspend {
			mux {
				pins = "gpio128";
				function = "gpio";
			};

			config {
				pins = "gpio128";
				drive-strength = <2>;
				bias-pull-down;
			};
		};
	};

	pmx_ts_int_suspend {
		ts_int_suspend: ts_int_suspend {
			mux {
				pins = "gpio129";
				function = "gpio";
			};

			config {
				pins = "gpio129";
				drive-strength = <2>;
				bias-pull-down;
			};
		};
	};

	pmx_ts_release {
		ts_release: ts_release {
			mux {
				pins = "gpio128", "gpio129";
				function = "gpio";
			};

			config {
				pins = "gpio128", "gpio129";
				drive-strength = <2>;
				bias-disable;
			};
		};
	};
};
